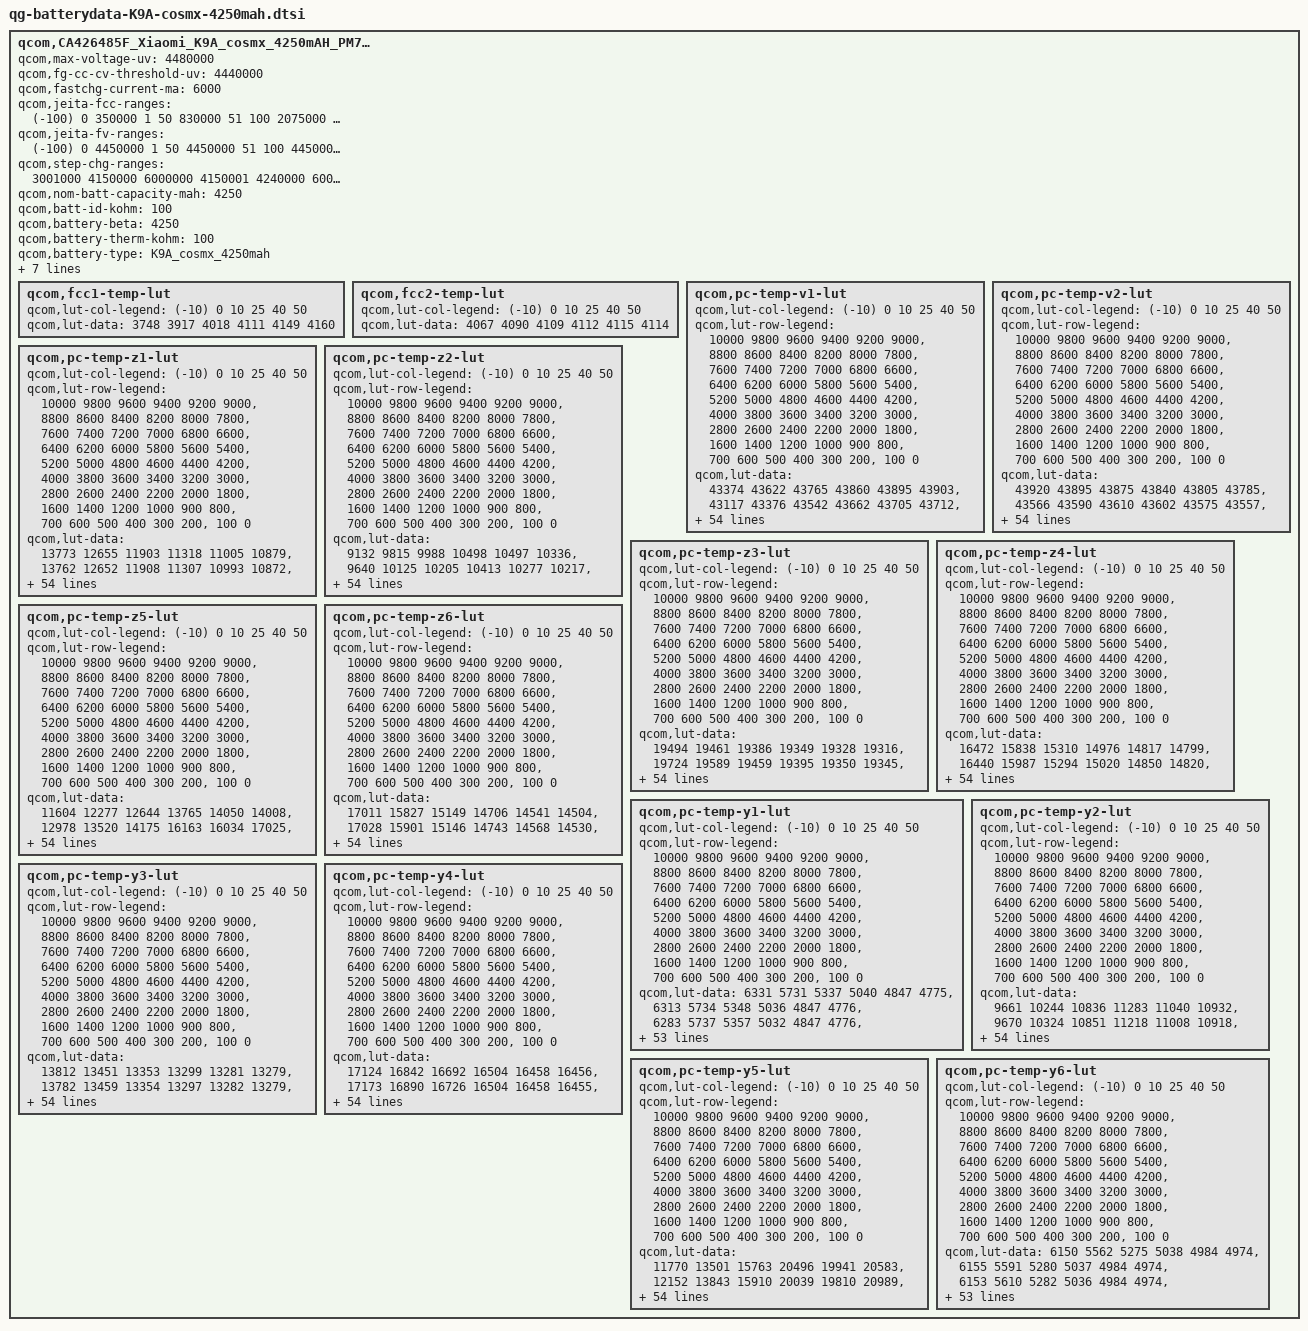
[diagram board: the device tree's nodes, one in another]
qcom,CA426485F_Xiaomi_K9A_cosmx_4250mAH_PM7150 {
	/* 4839394_Xiaomi_K9Acosmx_4250mAh_averaged_MasterSlave_Oct12th2020_DTSI */
	qcom,max-voltage-uv = <4480000>;
	qcom,fg-cc-cv-threshold-uv = <4440000>;
	qcom,fastchg-current-ma = <6000>;
	qcom,jeita-fcc-ranges = <(-100)  0   350000
				1  50  830000
				51  100  2075000
				101 150  3320000
				151 480  6000000
				481 600  2075000>;
	qcom,jeita-fv-ranges = <(-100)  0   4450000
				1   50  4450000
				51  100  4450000
				101 150  4450000
				151 480  4480000
				481 600  4100000>;
	qcom,step-chg-ranges = <3001000  4150000  6000000
				4150001  4240000  6000000
				4240001  4350000  5400000
				4350001  4400000  5400000
				4400001  4440000  5400000
				4440001  4480000  3320000>;

	qcom,nom-batt-capacity-mah = <4250>;
	qcom,batt-id-kohm = <100>;
	qcom,battery-beta = <4250>;
	qcom,battery-therm-kohm = <100>;
	qcom,battery-type = "K9A_cosmx_4250mah";
	qcom,qg-batt-profile-ver = <100>;
	qcom,taper-fcc;

	mi,six-pin-battery;
	mi,use-bq-pump;
	mi,step-chg-hysteresis = <5000>;
	mi-ffc-current-cfg = <350 850000 850000 (-500) (-600)>;	/* specification 100% current: 828mA */

	qcom,fcc1-temp-lut {
		qcom,lut-col-legend = <(-10) 0 10 25 40 50>;
		qcom,lut-data = <3748 3917 4018 4111 4149 4160>;
	};

	qcom,fcc2-temp-lut {
		qcom,lut-col-legend = <(-10) 0 10 25 40 50>;
		qcom,lut-data = <4067 4090 4109 4112 4115 4114>;
	};

	qcom,pc-temp-v1-lut {
		qcom,lut-col-legend = <(-10) 0 10 25 40 50>;
		qcom,lut-row-legend = <10000 9800 9600 9400 9200 9000>,
			<8800 8600 8400 8200 8000 7800>,
			<7600 7400 7200 7000 6800 6600>,
			<6400 6200 6000 5800 5600 5400>,
			<5200 5000 4800 4600 4400 4200>,
			<4000 3800 3600 3400 3200 3000>,
			<2800 2600 2400 2200 2000 1800>,
			<1600 1400 1200 1000 900 800>,
			<700 600 500 400 300 200>,
			<100 0>;
		qcom,lut-data = <43374 43622 43765 43860 43895 43903>,
			<43117 43376 43542 43662 43705 43712>,
			<42869 43136 43315 43452 43502 43511>,
			<42630 42899 43085 43233 43289 43302>,
			<42398 42665 42850 43007 43067 43085>,
			<42171 42428 42614 42771 42834 42857>,
			<41949 42192 42378 42533 42597 42622>,
			<41732 41963 42142 42296 42361 42386>,
			<41518 41739 41911 42061 42127 42149>,
			<41307 41521 41684 41828 41894 41914>,
			<41099 41308 41463 41598 41663 41684>,
			<40897 41100 41248 41374 41435 41459>,
			<40700 40897 41041 41157 41213 41237>,
			<40507 40699 40838 40948 40998 41021>,
			<40314 40505 40634 40745 40788 40809>,
			<40123 40319 40435 40548 40587 40606>,
			<39952 40138 40252 40358 40394 40411>,
			<39805 39966 40088 40181 40211 40224>,
			<39674 39810 39927 40017 40047 40055>,
			<39555 39668 39759 39837 39877 39885>,
			<39448 39529 39589 39603 39660 39678>,
			<39344 39382 39404 39350 39403 39427>,
			<39227 39232 39173 39155 39189 39205>,
			<39092 39080 38940 39002 39030 39041>,
			<38959 38917 38789 38872 38893 38902>,
			<38847 38759 38690 38758 38770 38776>,
			<38744 38641 38610 38660 38658 38664>,
			<38652 38550 38537 38568 38557 38561>,
			<38575 38478 38471 38481 38465 38465>,
			<38506 38418 38411 38402 38380 38376>,
			<38448 38368 38356 38332 38304 38298>,
			<38399 38324 38306 38268 38235 38227>,
			<38357 38287 38262 38213 38172 38161>,
			<38318 38253 38222 38166 38116 38098>,
			<38283 38222 38186 38124 38065 38040>,
			<38249 38195 38153 38081 38012 37977>,
			<38213 38166 38122 38041 37957 37911>,
			<38176 38124 38079 37992 37896 37838>,
			<38136 38060 38006 37920 37817 37753>,
			<38079 37979 37911 37824 37720 37655>,
			<37975 37876 37803 37719 37614 37548>,
			<37848 37743 37673 37599 37496 37426>,
			<37704 37588 37525 37460 37362 37291>,
			<37558 37431 37358 37293 37195 37129>,
			<37423 37337 37223 37159 37081 37011>,
			<37306 37237 37146 37081 37010 36952>,
			<37261 37198 37120 37060 36990 36933>,
			<37223 37166 37100 37042 36975 36915>,
			<37186 37132 37072 37023 36950 36891>,
			<37132 37055 36992 36943 36860 36792>,
			<36973 36822 36703 36635 36530 36449>,
			<36624 36362 36233 36170 36072 35991>,
			<36099 35774 35628 35576 35482 35395>,
			<35422 34983 34800 34764 34676 34578>,
			<34274 33686 33461 33486 33419 33295>,
			<30000 30000 30000 30000 30000 30000>;
	};

	qcom,pc-temp-v2-lut {
		qcom,lut-col-legend = <(-10) 0 10 25 40 50>;
		qcom,lut-row-legend = <10000 9800 9600 9400 9200 9000>,
			<8800 8600 8400 8200 8000 7800>,
			<7600 7400 7200 7000 6800 6600>,
			<6400 6200 6000 5800 5600 5400>,
			<5200 5000 4800 4600 4400 4200>,
			<4000 3800 3600 3400 3200 3000>,
			<2800 2600 2400 2200 2000 1800>,
			<1600 1400 1200 1000 900 800>,
			<700 600 500 400 300 200>,
			<100 0>;
		qcom,lut-data = <43920 43895 43875 43840 43805 43785>,
			<43566 43590 43610 43602 43575 43557>,
			<43237 43303 43351 43366 43344 43327>,
			<42935 43038 43101 43129 43113 43099>,
			<42660 42797 42858 42894 42883 42871>,
			<42398 42560 42617 42658 42651 42641>,
			<42139 42310 42376 42421 42416 42407>,
			<41886 42055 42134 42183 42179 42170>,
			<41648 41816 41896 41949 41945 41937>,
			<41415 41597 41660 41716 41713 41704>,
			<41204 41388 41428 41487 41484 41475>,
			<41054 41188 41200 41264 41261 41253>,
			<40951 41001 40976 41045 41042 41033>,
			<40818 40797 40767 40834 40830 40822>,
			<40505 40543 40582 40628 40623 40615>,
			<40072 40267 40404 40429 40424 40416>,
			<39767 40029 40207 40240 40235 40227>,
			<39577 39826 39993 40064 40061 40051>,
			<39406 39627 39770 39877 39880 39871>,
			<39212 39408 39536 39657 39677 39677>,
			<39011 39181 39296 39421 39464 39475>,
			<38815 38974 39085 39203 39253 39270>,
			<38612 38790 38897 38998 39035 39048>,
			<38429 38617 38729 38816 38840 38847>,
			<38316 38442 38585 38673 38697 38702>,
			<38241 38266 38458 38553 38580 38585>,
			<38178 38141 38336 38446 38473 38477>,
			<38116 38074 38209 38346 38372 38375>,
			<38058 38024 38093 38256 38279 38282>,
			<38001 37977 38006 38170 38196 38197>,
			<37943 37932 37936 38091 38122 38120>,
			<37884 37888 37882 38017 38051 38047>,
			<37824 37841 37844 37949 37985 37982>,
			<37761 37792 37812 37884 37921 37918>,
			<37698 37743 37776 37820 37845 37836>,
			<37631 37693 37737 37754 37753 37730>,
			<37561 37639 37692 37687 37658 37620>,
			<37488 37575 37631 37614 37568 37522>,
			<37411 37500 37551 37538 37478 37429>,
			<37333 37416 37459 37454 37387 37336>,
			<37257 37319 37345 37360 37300 37248>,
			<37181 37211 37219 37256 37207 37154>,
			<37106 37097 37097 37126 37081 37029>,
			<37033 36974 36977 36980 36941 36887>,
			<36958 36871 36869 36898 36871 36821>,
			<36881 36789 36771 36849 36832 36785>,
			<36833 36753 36727 36832 36819 36771>,
			<36772 36722 36683 36812 36802 36755>,
			<36694 36672 36628 36772 36763 36711>,
			<36561 36574 36499 36637 36610 36527>,
			<36346 36336 36216 36263 36221 36123>,
			<36053 35925 35743 35729 35705 35597>,
			<35601 35307 35095 35027 35028 34907>,
			<34891 34390 34167 34022 34100 33973>,
			<33684 32791 32537 32386 32695 32545>,
			<31203 29386 27722 28383 28528 28234>;
	};

	qcom,pc-temp-z1-lut {
		qcom,lut-col-legend = <(-10) 0 10 25 40 50>;
		qcom,lut-row-legend = <10000 9800 9600 9400 9200 9000>,
			<8800 8600 8400 8200 8000 7800>,
			<7600 7400 7200 7000 6800 6600>,
			<6400 6200 6000 5800 5600 5400>,
			<5200 5000 4800 4600 4400 4200>,
			<4000 3800 3600 3400 3200 3000>,
			<2800 2600 2400 2200 2000 1800>,
			<1600 1400 1200 1000 900 800>,
			<700 600 500 400 300 200>,
			<100 0>;
		qcom,lut-data = <13773 12655 11903 11318 11005 10879>,
			<13762 12652 11908 11307 10993 10872>,
			<13740 12643 11910 11300 10984 10867>,
			<13698 12629 11906 11293 10978 10862>,
			<13654 12621 11888 11282 10972 10856>,
			<13627 12619 11869 11268 10964 10850>,
			<13606 12617 11852 11255 10954 10843>,
			<13593 12611 11836 11246 10948 10838>,
			<13584 12578 11828 11237 10944 10835>,
			<13566 12541 11822 11234 10941 10833>,
			<13550 12520 11817 11232 10939 10831>,
			<13546 12503 11813 11231 10936 10830>,
			<13545 12489 11802 11231 10935 10829>,
			<13545 12472 11797 11231 10934 10828>,
			<13539 12455 11798 11232 10934 10828>,
			<13528 12452 11799 11234 10934 10828>,
			<13520 12446 11801 11237 10935 10829>,
			<13521 12435 11807 11237 10935 10829>,
			<13532 12430 11814 11236 10937 10830>,
			<13541 12426 11815 11235 10939 10831>,
			<13560 12425 11815 11235 10939 10832>,
			<13579 12434 11815 11237 10939 10833>,
			<13579 12449 11816 11240 10940 10834>,
			<13564 12456 11817 11247 10943 10836>,
			<13552 12454 11822 11254 10947 10840>,
			<13554 12451 11845 11258 10951 10843>,
			<13560 12451 11865 11263 10954 10846>,
			<13566 12460 11862 11266 10957 10848>,
			<13575 12469 11851 11267 10961 10851>,
			<13586 12473 11846 11269 10965 10854>,
			<13600 12480 11854 11271 10968 10856>,
			<13625 12486 11865 11273 10972 10859>,
			<13655 12487 11868 11277 10975 10862>,
			<13672 12489 11867 11281 10980 10866>,
			<13679 12494 11866 11287 10984 10871>,
			<13688 12524 11870 11293 10988 10875>,
			<13692 12561 11878 11302 10993 10879>,
			<13690 12573 11889 11309 10997 10883>,
			<13688 12569 11905 11313 11002 10886>,
			<13691 12567 11922 11317 11006 10890>,
			<13702 12576 11931 11322 11010 10894>,
			<13710 12588 11940 11330 11013 10898>,
			<13695 12590 11942 11336 11017 10901>,
			<13706 12588 11950 11341 11022 10903>,
			<13748 12614 11949 11354 11026 10906>,
			<13706 12645 11962 11352 11031 10905>,
			<13693 12612 11963 11345 11029 10906>,
			<13719 12617 11964 11349 11029 10907>,
			<13701 12620 11969 11352 11033 10909>,
			<13705 12635 11965 11360 11040 10916>,
			<13747 12654 11975 11370 11050 10923>,
			<13758 12643 12003 11389 11057 10929>,
			<13738 12680 12027 11398 11066 10940>,
			<13759 12717 12080 11419 11080 10951>,
			<13759 12717 12080 11419 11080 10951>,
			<13759 12717 12080 11419 11080 10951>;
	};

	qcom,pc-temp-z2-lut {
		qcom,lut-col-legend = <(-10) 0 10 25 40 50>;
		qcom,lut-row-legend = <10000 9800 9600 9400 9200 9000>,
			<8800 8600 8400 8200 8000 7800>,
			<7600 7400 7200 7000 6800 6600>,
			<6400 6200 6000 5800 5600 5400>,
			<5200 5000 4800 4600 4400 4200>,
			<4000 3800 3600 3400 3200 3000>,
			<2800 2600 2400 2200 2000 1800>,
			<1600 1400 1200 1000 900 800>,
			<700 600 500 400 300 200>,
			<100 0>;
		qcom,lut-data = <9132 9815 9988 10498 10497 10336>,
			<9640 10125 10205 10413 10277 10217>,
			<9871 10171 10334 10412 10238 10167>,
			<9943 10185 10339 10414 10230 10146>,
			<9983 10186 10298 10403 10220 10128>,
			<9991 10168 10256 10356 10184 10098>,
			<9988 10140 10228 10314 10139 10064>,
			<9985 10124 10204 10302 10127 10056>,
			<9984 10111 10187 10294 10134 10077>,
			<9982 10100 10173 10294 10140 10100>,
			<9979 10090 10164 10302 10135 10103>,
			<9973 10081 10167 10310 10129 10099>,
			<9965 10073 10182 10307 10128 10099>,
			<9957 10064 10200 10299 10135 10109>,
			<9950 10057 10217 10296 10145 10121>,
			<9943 10055 10233 10308 10155 10129>,
			<9936 10062 10245 10325 10169 10135>,
			<9931 10071 10251 10336 10185 10143>,
			<9926 10074 10258 10350 10204 10157>,
			<9906 10075 10272 10372 10231 10176>,
			<9752 10077 10293 10433 10295 10206>,
			<9583 10085 10315 10509 10410 10261>,
			<9581 10106 10340 10518 10460 10299>,
			<9755 10127 10362 10454 10374 10287>,
			<9921 10151 10365 10401 10261 10249>,
			<9950 10173 10352 10401 10232 10204>,
			<9959 10179 10339 10408 10227 10102>,
			<9966 10180 10337 10410 10220 10032>,
			<9973 10181 10338 10407 10182 10036>,
			<9979 10181 10341 10404 10135 10048>,
			<9985 10182 10344 10408 10128 10059>,
			<9992 10184 10348 10424 10141 10080>,
			<10000 10186 10353 10440 10159 10106>,
			<10005 10188 10360 10450 10187 10137>,
			<10008 10191 10369 10460 10232 10176>,
			<10009 10194 10377 10475 10270 10217>,
			<10009 10197 10387 10499 10302 10263>,
			<9881 10203 10397 10524 10335 10305>,
			<9685 10211 10408 10550 10379 10336>,
			<9603 10217 10418 10575 10429 10362>,
			<9586 10219 10419 10580 10449 10372>,
			<9609 10219 10415 10562 10437 10370>,
			<9600 10227 10409 10544 10421 10365>,
			<9498 10244 10395 10529 10404 10348>,
			<9173 10158 10488 10545 10414 10331>,
			<9163 10182 10448 10514 10388 10317>,
			<9166 10318 10446 10467 10403 10326>,
			<9164 10373 10446 10476 10425 10347>,
			<9158 10571 10417 10475 10462 10396>,
			<9152 10675 10419 10506 10488 10433>,
			<9139 10396 10460 10513 10368 10273>,
			<9119 9946 10315 10484 10284 10181>,
			<9097 9760 10250 10402 10255 10122>,
			<9070 9568 10129 10345 10170 10055>,
			<9070 9568 10129 10345 10170 10055>,
			<9070 9568 10129 10345 10170 10055>;
	};

	qcom,pc-temp-z3-lut {
		qcom,lut-col-legend = <(-10) 0 10 25 40 50>;
		qcom,lut-row-legend = <10000 9800 9600 9400 9200 9000>,
			<8800 8600 8400 8200 8000 7800>,
			<7600 7400 7200 7000 6800 6600>,
			<6400 6200 6000 5800 5600 5400>,
			<5200 5000 4800 4600 4400 4200>,
			<4000 3800 3600 3400 3200 3000>,
			<2800 2600 2400 2200 2000 1800>,
			<1600 1400 1200 1000 900 800>,
			<700 600 500 400 300 200>,
			<100 0>;
		qcom,lut-data = <19494 19461 19386 19349 19328 19316>,
			<19724 19589 19459 19395 19350 19345>,
			<19813 19614 19510 19411 19364 19360>,
			<19841 19622 19528 19420 19374 19367>,
			<19856 19629 19537 19424 19382 19373>,
			<19858 19638 19542 19427 19388 19377>,
			<19850 19647 19543 19429 19392 19381>,
			<19842 19651 19544 19426 19392 19382>,
			<19839 19653 19544 19422 19386 19380>,
			<19839 19654 19541 19418 19379 19377>,
			<19840 19654 19536 19416 19377 19374>,
			<19841 19651 19527 19414 19375 19371>,
			<19844 19648 19514 19410 19373 19368>,
			<19847 19645 19506 19405 19373 19366>,
			<19853 19640 19505 19401 19372 19365>,
			<19859 19635 19504 19398 19370 19363>,
			<19862 19628 19502 19396 19368 19360>,
			<19857 19621 19495 19395 19366 19358>,
			<19843 19616 19488 19395 19360 19355>,
			<19820 19611 19488 19395 19354 19352>,
			<19702 19609 19490 19403 19358 19352>,
			<19575 19611 19493 19416 19370 19359>,
			<19572 19617 19500 19417 19376 19367>,
			<19694 19623 19508 19406 19376 19376>,
			<19808 19631 19509 19397 19377 19386>,
			<19822 19638 19505 19401 19380 19389>,
			<19824 19639 19502 19413 19391 19389>,
			<19825 19636 19500 19420 19398 19389>,
			<19824 19631 19500 19423 19395 19387>,
			<19819 19627 19499 19425 19389 19382>,
			<19813 19622 19499 19424 19383 19376>,
			<19806 19618 19500 19420 19379 19369>,
			<19797 19615 19499 19416 19374 19362>,
			<19789 19612 19498 19412 19368 19355>,
			<19783 19608 19496 19407 19363 19348>,
			<19777 19602 19493 19404 19360 19346>,
			<19767 19596 19490 19401 19357 19345>,
			<19683 19590 19487 19399 19356 19346>,
			<19558 19584 19482 19397 19356 19346>,
			<19499 19578 19477 19395 19357 19346>,
			<19486 19571 19474 19393 19357 19347>,
			<19499 19564 19471 19391 19357 19350>,
			<19495 19559 19468 19387 19357 19352>,
			<19443 19550 19462 19383 19357 19351>,
			<19286 19267 19440 19374 19348 19349>,
			<19289 19262 19429 19370 19343 19340>,
			<19288 19261 19425 19366 19339 19332>,
			<19288 19261 19415 19363 19333 19329>,
			<19289 19260 19404 19355 19330 19323>,
			<19290 19260 19399 19354 19331 19322>,
			<19293 19261 19400 19356 19345 19341>,
			<19298 19263 19371 19360 19347 19340>,
			<19306 19265 19370 19360 19347 19340>,
			<19320 19269 19371 19362 19350 19345>,
			<19320 19269 19371 19362 19350 19345>,
			<19320 19269 19371 19362 19350 19345>;
	};

	qcom,pc-temp-z4-lut {
		qcom,lut-col-legend = <(-10) 0 10 25 40 50>;
		qcom,lut-row-legend = <10000 9800 9600 9400 9200 9000>,
			<8800 8600 8400 8200 8000 7800>,
			<7600 7400 7200 7000 6800 6600>,
			<6400 6200 6000 5800 5600 5400>,
			<5200 5000 4800 4600 4400 4200>,
			<4000 3800 3600 3400 3200 3000>,
			<2800 2600 2400 2200 2000 1800>,
			<1600 1400 1200 1000 900 800>,
			<700 600 500 400 300 200>,
			<100 0>;
		qcom,lut-data = <16472 15838 15310 14976 14817 14799>,
			<16440 15987 15294 15020 14850 14820>,
			<16369 15930 15258 14978 14846 14821>,
			<16200 15752 15199 14906 14814 14798>,
			<15983 15576 15093 14857 14782 14770>,
			<15817 15438 14994 14819 14758 14748>,
			<15687 15312 14930 14787 14736 14728>,
			<15573 15210 14878 14761 14722 14716>,
			<15470 15124 14837 14740 14712 14708>,
			<15372 15053 14802 14728 14705 14703>,
			<15302 14995 14776 14721 14700 14698>,
			<15267 14947 14761 14716 14697 14695>,
			<15243 14909 14750 14712 14692 14691>,
			<15230 14879 14744 14710 14687 14687>,
			<15227 14854 14741 14707 14682 14684>,
			<15226 14836 14740 14705 14679 14681>,
			<15223 14823 14737 14702 14676 14678>,
			<15200 14812 14730 14700 14674 14675>,
			<15160 14801 14724 14697 14673 14671>,
			<15147 14787 14725 14695 14672 14668>,
			<15230 14778 14731 14725 14690 14679>,
			<15325 14776 14740 14779 14745 14731>,
			<15324 14776 14788 14806 14771 14764>,
			<15224 14778 14851 14821 14769 14754>,
			<15137 14798 14865 14828 14765 14736>,
			<15139 14828 14858 14816 14754 14721>,
			<15161 14841 14847 14785 14727 14707>,
			<15180 14844 14835 14763 14708 14697>,
			<15184 14845 14820 14748 14703 14692>,
			<15185 14842 14807 14738 14700 14689>,
			<15184 14834 14796 14736 14698 14686>,
			<15178 14825 14788 14736 14695 14682>,
			<15164 14817 14782 14736 14694 14680>,
			<15149 14808 14779 14736 14694 14679>,
			<15130 14800 14775 14738 14694 14678>,
			<15110 14791 14772 14739 14695 14678>,
			<15094 14781 14767 14739 14697 14680>,
			<15132 14773 14764 14740 14699 14685>,
			<15200 14764 14762 14740 14703 14690>,
			<15231 14757 14760 14741 14708 14696>,
			<15218 14751 14755 14740 14709 14698>,
			<15182 14746 14742 14725 14698 14691>,
			<15158 14735 14731 14712 14692 14687>,
			<15160 14727 14720 14705 14694 14693>,
			<15255 14933 14685 14677 14676 14678>,
			<15250 14929 14671 14662 14659 14656>,
			<15243 14927 14665 14653 14650 14649>,
			<15230 14920 14663 14645 14639 14636>,
			<15224 14913 14666 14641 14628 14624>,
			<15207 14907 14669 14641 14628 14626>,
			<15206 14908 14679 14656 14647 14652>,
			<15227 14928 14721 14656 14649 14657>,
			<15276 14941 14728 14657 14651 14660>,
			<15349 14964 14738 14655 14648 14655>,
			<15349 14964 14738 14655 14648 14655>,
			<15349 14964 14738 14655 14648 14655>;
	};

	qcom,pc-temp-z5-lut {
		qcom,lut-col-legend = <(-10) 0 10 25 40 50>;
		qcom,lut-row-legend = <10000 9800 9600 9400 9200 9000>,
			<8800 8600 8400 8200 8000 7800>,
			<7600 7400 7200 7000 6800 6600>,
			<6400 6200 6000 5800 5600 5400>,
			<5200 5000 4800 4600 4400 4200>,
			<4000 3800 3600 3400 3200 3000>,
			<2800 2600 2400 2200 2000 1800>,
			<1600 1400 1200 1000 900 800>,
			<700 600 500 400 300 200>,
			<100 0>;
		qcom,lut-data = <11604 12277 12644 13765 14050 14008>,
			<12978 13520 14175 16163 16034 17025>,
			<13898 14064 15418 16981 17303 18657>,
			<14520 14371 16268 17512 18182 19461>,
			<15004 14750 16849 18142 19085 20213>,
			<15400 15368 17483 18803 20492 21375>,
			<15702 16153 18406 19478 21785 22696>,
			<15999 16935 19547 20243 22017 23767>,
			<16444 17691 20783 21064 22003 24779>,
			<17135 18441 22341 21759 21994 25506>,
			<17728 19219 23670 22429 22169 25615>,
			<17930 20067 24143 22845 22595 25458>,
			<18021 20891 24352 22814 23142 25507>,
			<18144 21698 24671 22669 24103 26251>,
			<18509 22529 26160 22619 25173 27322>,
			<19098 23102 28323 23019 26192 28223>,
			<19406 23448 28878 23732 27181 29135>,
			<19327 23774 27991 24522 27411 29924>,
			<19116 24120 27125 25750 26257 30737>,
			<18794 24663 28319 27395 25064 31363>,
			<17313 25557 32711 30770 25522 31165>,
			<15883 27822 36693 34592 27198 29697>,
			<16257 32356 39573 34427 27896 27862>,
			<18745 36921 41782 26947 23997 25208>,
			<21172 41795 41574 20651 19155 22400>,
			<21859 46021 37084 20778 19199 22100>,
			<22222 46730 32788 21954 22407 24204>,
			<22414 44476 31855 23489 25059 26496>,
			<22394 41615 31441 26078 26084 28002>,
			<22221 39886 31494 28977 26834 29241>,
			<22003 38394 32581 31198 27659 29485>,
			<21789 37526 34308 33213 28595 28881>,
			<21548 37263 35790 34433 29245 28251>,
			<21379 37100 37399 35031 29529 27992>,
			<21316 36816 38593 35400 29725 27713>,
			<21268 36095 39121 35431 29824 27680>,
			<21173 35407 39466 35249 29833 28758>,
			<19498 35441 39448 34944 29818 29913>,
			<16956 36117 38938 34203 29651 29600>,
			<15803 36643 38307 32992 29213 28291>,
			<15935 36240 37974 32102 29038 27687>,
			<16481 35413 37680 31556 29202 29119>,
			<16074 36150 37141 30789 29302 30177>,
			<14368 37538 36030 29357 28988 29796>,
			<10983 11872 37671 31917 27759 31535>,
			<10947 11352 33155 32114 26404 26855>,
			<10905 11312 31067 31143 26011 23585>,
			<10857 11251 26350 31745 26482 26518>,
			<10831 11206 23512 28153 30752 31455>,
			<10828 11213 22949 27688 31129 30535>,
			<10838 11276 22344 22698 26527 26530>,
			<10826 11298 15620 22377 24498 22014>,
			<10778 11218 14919 21275 22266 19796>,
			<10739 11136 14393 21096 21602 18918>,
			<10739 11136 14393 21096 21602 18918>,
			<10739 11136 14393 21096 21602 18918>;
	};

	qcom,pc-temp-z6-lut {
		qcom,lut-col-legend = <(-10) 0 10 25 40 50>;
		qcom,lut-row-legend = <10000 9800 9600 9400 9200 9000>,
			<8800 8600 8400 8200 8000 7800>,
			<7600 7400 7200 7000 6800 6600>,
			<6400 6200 6000 5800 5600 5400>,
			<5200 5000 4800 4600 4400 4200>,
			<4000 3800 3600 3400 3200 3000>,
			<2800 2600 2400 2200 2000 1800>,
			<1600 1400 1200 1000 900 800>,
			<700 600 500 400 300 200>,
			<100 0>;
		qcom,lut-data = <17011 15827 15149 14706 14541 14504>,
			<17028 15901 15146 14743 14568 14530>,
			<16987 15863 15138 14727 14569 14535>,
			<16868 15748 15116 14697 14560 14529>,
			<16713 15637 15055 14675 14550 14521>,
			<16587 15555 14994 14656 14542 14514>,
			<16479 15482 14953 14638 14534 14507>,
			<16382 15420 14918 14622 14526 14501>,
			<16298 15366 14888 14608 14517 14496>,
			<16223 15319 14863 14599 14511 14491>,
			<16173 15278 14841 14594 14507 14487>,
			<16157 15242 14826 14590 14503 14484>,
			<16147 15210 14814 14586 14500 14480>,
			<16142 15182 14806 14582 14497 14478>,
			<16143 15157 14803 14579 14495 14475>,
			<16147 15139 14801 14577 14492 14472>,
			<16149 15126 14798 14575 14490 14470>,
			<16141 15117 14792 14574 14488 14467>,
			<16125 15111 14788 14573 14484 14464>,
			<16112 15106 14789 14572 14481 14461>,
			<16098 15103 14794 14590 14491 14466>,
			<16087 15105 14803 14622 14521 14493>,
			<16089 15111 14829 14632 14536 14510>,
			<16111 15120 14861 14634 14536 14510>,
			<16140 15136 14868 14635 14536 14509>,
			<16159 15155 14865 14633 14534 14508>,
			<16176 15163 14862 14627 14530 14503>,
			<16190 15165 14858 14622 14525 14498>,
			<16196 15166 14853 14620 14521 14495>,
			<16200 15164 14850 14617 14518 14491>,
			<16202 15161 14847 14616 14514 14487>,
			<16201 15157 14845 14615 14511 14483>,
			<16197 15155 14844 14614 14508 14478>,
			<16194 15153 14844 14613 14506 14474>,
			<16193 15151 14844 14612 14503 14470>,
			<16192 15149 14844 14612 14503 14469>,
			<16191 15146 14844 14613 14503 14470>,
			<16181 15146 14844 14613 14503 14472>,
			<16166 15148 14845 14614 14505 14474>,
			<16160 15149 14847 14615 14509 14478>,
			<16166 15152 14847 14615 14510 14479>,
			<16172 15156 14847 14610 14506 14478>,
			<16177 15162 14847 14605 14504 14478>,
			<16173 15166 14846 14603 14506 14481>,
			<16156 15136 14833 14590 14494 14474>,
			<16160 15132 14825 14583 14484 14460>,
			<16158 15133 14820 14578 14479 14453>,
			<16153 15132 14816 14574 14471 14445>,
			<16163 15133 14816 14570 14466 14437>,
			<16171 15140 14820 14572 14467 14438>,
			<16187 15152 14833 14584 14485 14462>,
			<16222 15172 14844 14589 14489 14466>,
			<16276 15195 14857 14595 14492 14469>,
			<16361 15230 14881 14602 14496 14473>,
			<16361 15230 14881 14602 14496 14473>,
			<16361 15230 14881 14602 14496 14473>;
	};

	qcom,pc-temp-y1-lut {
		qcom,lut-col-legend = <(-10) 0 10 25 40 50>;
		qcom,lut-row-legend = <10000 9800 9600 9400 9200 9000>,
			<8800 8600 8400 8200 8000 7800>,
			<7600 7400 7200 7000 6800 6600>,
			<6400 6200 6000 5800 5600 5400>,
			<5200 5000 4800 4600 4400 4200>,
			<4000 3800 3600 3400 3200 3000>,
			<2800 2600 2400 2200 2000 1800>,
			<1600 1400 1200 1000 900 800>,
			<700 600 500 400 300 200>,
			<100 0>;
		qcom,lut-data = <6331 5731 5337 5040 4847 4775>,
			<6313 5734 5348 5036 4847 4776>,
			<6283 5737 5357 5032 4847 4776>,
			<6248 5738 5364 5027 4846 4776>,
			<6218 5739 5369 5023 4845 4775>,
			<6201 5738 5371 5020 4843 4774>,
			<6200 5735 5369 5018 4841 4772>,
			<6200 5731 5366 5016 4839 4770>,
			<6201 5729 5362 5015 4838 4769>,
			<6224 5729 5360 5013 4836 4768>,
			<6252 5730 5358 5012 4835 4768>,
			<6257 5731 5359 5011 4834 4767>,
			<6254 5733 5361 5009 4832 4767>,
			<6249 5734 5363 5009 4831 4766>,
			<6238 5742 5369 5009 4830 4765>,
			<6222 5753 5376 5011 4829 4764>,
			<6219 5756 5377 5012 4829 4764>,
			<6231 5756 5375 5013 4828 4765>,
			<6242 5755 5374 5013 4828 4765>,
			<6239 5754 5380 5013 4829 4765>,
			<6228 5750 5391 5013 4832 4766>,
			<6224 5751 5393 5014 4833 4766>,
			<6229 5764 5384 5018 4835 4767>,
			<6234 5777 5375 5022 4836 4769>,
			<6237 5775 5378 5025 4838 4771>,
			<6240 5764 5389 5027 4840 4772>,
			<6241 5758 5393 5028 4842 4774>,
			<6234 5755 5387 5030 4844 4776>,
			<6222 5751 5379 5033 4847 4777>,
			<6217 5750 5379 5034 4849 4780>,
			<6216 5751 5384 5036 4851 4782>,
			<6216 5754 5389 5039 4853 4784>,
			<6228 5756 5387 5043 4857 4786>,
			<6270 5759 5383 5049 4861 4788>,
			<6293 5762 5383 5054 4864 4790>,
			<6264 5766 5386 5059 4865 4792>,
			<6223 5771 5389 5062 4867 4794>,
			<6218 5767 5391 5060 4870 4796>,
			<6250 5753 5394 5057 4874 4799>,
			<6276 5744 5397 5056 4876 4800>,
			<6264 5749 5398 5062 4876 4801>,
			<6238 5758 5399 5069 4877 4802>,
			<6227 5762 5401 5075 4880 4804>,
			<6239 5764 5404 5080 4884 4808>,
			<6253 5767 5406 5087 4889 4810>,
			<6271 5769 5410 5098 4893 4812>,
			<6274 5772 5412 5100 4892 4811>,
			<6256 5778 5416 5098 4892 4810>,
			<6238 5809 5428 5095 4890 4810>,
			<6296 5805 5439 5099 4890 4812>,
			<6323 5805 5427 5100 4893 4814>,
			<6423 5820 5434 5111 4899 4821>,
			<6482 5868 5470 5126 4907 4827>,
			<6601 5959 5508 5136 4918 4834>,
			<6601 5959 5508 5136 4918 4834>,
			<6601 5959 5508 5136 4918 4834>;
	};

	qcom,pc-temp-y2-lut {
		qcom,lut-col-legend = <(-10) 0 10 25 40 50>;
		qcom,lut-row-legend = <10000 9800 9600 9400 9200 9000>,
			<8800 8600 8400 8200 8000 7800>,
			<7600 7400 7200 7000 6800 6600>,
			<6400 6200 6000 5800 5600 5400>,
			<5200 5000 4800 4600 4400 4200>,
			<4000 3800 3600 3400 3200 3000>,
			<2800 2600 2400 2200 2000 1800>,
			<1600 1400 1200 1000 900 800>,
			<700 600 500 400 300 200>,
			<100 0>;
		qcom,lut-data = <9661 10244 10836 11283 11040 10932>,
			<9670 10324 10851 11218 11008 10918>,
			<9680 10408 10864 11147 10965 10895>,
			<9689 10483 10874 11077 10920 10866>,
			<9697 10540 10881 11018 10879 10835>,
			<9701 10567 10884 10977 10853 10805>,
			<9700 10557 10883 10955 10840 10771>,
			<9698 10530 10878 10940 10829 10732>,
			<9695 10528 10873 10926 10817 10716>,
			<9688 10738 10862 10909 10802 10722>,
			<9682 10980 10854 10898 10790 10728>,
			<9681 10968 10869 10901 10785 10719>,
			<9682 10802 10937 10919 10781 10699>,
			<9683 10701 11017 10934 10780 10684>,
			<9680 10808 11113 10945 10773 10678>,
			<9676 10982 11210 10960 10764 10675>,
			<9673 11046 11264 11002 10779 10681>,
			<9672 11068 11302 11119 10861 10697>,
			<9670 11080 11320 11205 10947 10724>,
			<9670 11059 11289 11206 11007 10811>,
			<9669 10982 11224 11195 11062 10941>,
			<9668 10849 11193 11191 11081 10982>,
			<9668 10363 11185 11180 11072 10983>,
			<9667 9855 11178 11173 11061 10984>,
			<9666 9748 11167 11194 11070 10993>,
			<9666 9715 11153 11242 11091 11012>,
			<9665 9699 11130 11290 11117 11038>,
			<9665 9692 11078 11333 11156 11090>,
			<9664 9687 11014 11371 11197 11150>,
			<9664 9682 10924 11395 11222 11186>,
			<9663 9678 10655 11414 11241 11220>,
			<9663 9674 10470 11423 11261 11237>,
			<9663 9671 10596 11421 11295 11234>,
			<9663 9669 10837 11416 11328 11224>,
			<9662 9667 10895 11407 11331 11219>,
			<9662 9665 10840 11379 11316 11209>,
			<9662 9664 10745 11343 11295 11196>,
			<9662 9663 10465 11307 11264 11186>,
			<9662 9662 9980 11266 11223 11175>,
			<9661 9661 9756 11235 11203 11159>,
			<9661 9660 9714 11210 11201 11117>,
			<9661 9660 9690 11182 11200 11068>,
			<9661 9660 9680 11135 11170 11038>,
			<9660 9659 9674 11058 11104 11013>,
			<9660 9659 9669 10990 11014 10922>,
			<9658 9659 9665 10941 10937 10813>,
			<9658 9658 9664 10938 10952 10820>,
			<9656 9658 9663 10944 10979 10822>,
			<9656 9657 9666 11012 11010 10826>,
			<9655 9657 9664 11030 10964 10849>,
			<9653 9656 9661 10932 10959 10799>,
			<9650 9654 9658 10794 10893 10723>,
			<9649 9651 9656 10656 10772 10635>,
			<9648 9649 9653 10575 10693 10467>,
			<9648 9649 9653 10575 10693 10467>,
			<9648 9649 9653 10575 10693 10467>;
	};

	qcom,pc-temp-y3-lut {
		qcom,lut-col-legend = <(-10) 0 10 25 40 50>;
		qcom,lut-row-legend = <10000 9800 9600 9400 9200 9000>,
			<8800 8600 8400 8200 8000 7800>,
			<7600 7400 7200 7000 6800 6600>,
			<6400 6200 6000 5800 5600 5400>,
			<5200 5000 4800 4600 4400 4200>,
			<4000 3800 3600 3400 3200 3000>,
			<2800 2600 2400 2200 2000 1800>,
			<1600 1400 1200 1000 900 800>,
			<700 600 500 400 300 200>,
			<100 0>;
		qcom,lut-data = <13812 13451 13353 13299 13281 13279>,
			<13782 13459 13354 13297 13282 13279>,
			<13754 13464 13355 13295 13282 13280>,
			<13727 13467 13356 13294 13282 13280>,
			<13703 13468 13357 13294 13283 13281>,
			<13680 13468 13358 13294 13283 13282>,
			<13661 13466 13360 13294 13284 13282>,
			<13644 13461 13362 13296 13284 13283>,
			<13625 13460 13363 13296 13285 13283>,
			<13597 13475 13363 13297 13286 13284>,
			<13573 13493 13363 13297 13286 13284>,
			<13573 13483 13360 13298 13287 13284>,
			<13590 13436 13353 13300 13287 13285>,
			<13601 13407 13349 13301 13288 13286>,
			<13582 13406 13352 13301 13288 13286>,
			<13549 13406 13357 13302 13288 13286>,
			<13539 13403 13357 13302 13289 13287>,
			<13542 13393 13351 13302 13292 13288>,
			<13546 13381 13343 13301 13294 13289>,
			<13552 13369 13337 13299 13293 13288>,
			<13561 13356 13330 13296 13290 13288>,
			<13565 13352 13324 13294 13287 13286>,
			<13559 13359 13320 13290 13283 13282>,
			<13550 13368 13316 13288 13280 13279>,
			<13552 13363 13313 13288 13280 13278>,
			<13575 13342 13310 13288 13280 13278>,
			<13605 13330 13309 13288 13280 13278>,
			<13632 13340 13308 13288 13279 13278>,
			<13662 13360 13307 13288 13278 13277>,
			<13694 13380 13306 13287 13278 13277>,
			<13729 13402 13303 13286 13278 13276>,
			<13765 13428 13301 13286 13278 13276>,
			<13800 13458 13304 13286 13278 13277>,
			<13834 13493 13309 13286 13279 13278>,
			<13869 13536 13313 13286 13279 13278>,
			<13905 13591 13316 13286 13278 13277>,
			<13940 13651 13320 13286 13278 13276>,
			<13972 13709 13328 13286 13278 13276>,
			<14002 13768 13343 13286 13278 13276>,
			<14031 13822 13359 13286 13278 13277>,
			<14060 13871 13376 13288 13279 13278>,
			<14091 13915 13396 13290 13281 13279>,
			<14128 13950 13425 13291 13280 13278>,
			<14172 13977 13469 13292 13279 13277>,
			<14236 14013 13535 13295 13280 13278>,
			<14349 14066 13627 13301 13285 13283>,
			<14431 14114 13684 13306 13288 13286>,
			<14566 14179 13718 13310 13290 13287>,
			<14691 14182 13636 13306 13289 13286>,
			<14758 14236 13675 13304 13286 13283>,
			<15278 14443 13773 13301 13283 13281>,
			<16888 14867 13974 13304 13287 13283>,
			<21144 16413 14316 13313 13290 13287>,
			<36375 22612 15178 13333 13296 13295>,
			<36375 22612 15178 13333 13296 13295>,
			<36375 22612 15178 13333 13296 13295>;
	};

	qcom,pc-temp-y4-lut {
		qcom,lut-col-legend = <(-10) 0 10 25 40 50>;
		qcom,lut-row-legend = <10000 9800 9600 9400 9200 9000>,
			<8800 8600 8400 8200 8000 7800>,
			<7600 7400 7200 7000 6800 6600>,
			<6400 6200 6000 5800 5600 5400>,
			<5200 5000 4800 4600 4400 4200>,
			<4000 3800 3600 3400 3200 3000>,
			<2800 2600 2400 2200 2000 1800>,
			<1600 1400 1200 1000 900 800>,
			<700 600 500 400 300 200>,
			<100 0>;
		qcom,lut-data = <17124 16842 16692 16504 16458 16456>,
			<17173 16890 16726 16504 16458 16455>,
			<17228 16953 16760 16504 16458 16455>,
			<17278 17016 16789 16504 16458 16454>,
			<17317 17067 16810 16504 16457 16454>,
			<17336 17092 16820 16503 16457 16453>,
			<17330 17090 16815 16503 16457 16453>,
			<17314 17080 16804 16501 16457 16453>,
			<17308 17065 16797 16501 16457 16453>,
			<17337 17029 16793 16503 16458 16453>,
			<17379 16995 16791 16506 16459 16454>,
			<17403 17023 16797 16509 16462 16455>,
			<17420 17147 16820 16513 16465 16457>,
			<17428 17222 16843 16518 16469 16460>,
			<17323 17160 16862 16527 16475 16463>,
			<17117 17052 16878 16540 16481 16468>,
			<17011 16997 16877 16560 16491 16476>,
			<16976 16976 16857 16593 16507 16488>,
			<16943 16953 16828 16613 16521 16501>,
			<16885 16912 16785 16604 16529 16512>,
			<16806 16856 16728 16580 16534 16523>,
			<16742 16802 16685 16554 16531 16523>,
			<16692 16749 16652 16518 16496 16489>,
			<16655 16699 16627 16492 16463 16458>,
			<16648 16652 16611 16488 16460 16455>,
			<16647 16606 16601 16486 16460 16455>,
			<16647 16586 16585 16486 16460 16455>,
			<16648 16587 16549 16489 16463 16457>,
			<16651 16589 16513 16493 16469 16461>,
			<16655 16593 16505 16497 16474 16466>,
			<16659 16602 16512 16501 16482 16473>,
			<16664 16614 16520 16503 16489 16481>,
			<16668 16626 16530 16503 16497 16492>,
			<16673 16640 16545 16502 16504 16503>,
			<16677 16651 16562 16500 16504 16503>,
			<16681 16658 16588 16490 16491 16489>,
			<16685 16663 16614 16483 16476 16475>,
			<16686 16669 16634 16482 16467 16469>,
			<16687 16675 16651 16482 16459 16464>,
			<16688 16679 16658 16483 16458 16463>,
			<16692 16680 16659 16493 16465 16472>,
			<16703 16681 16660 16505 16473 16480>,
			<16718 16682 16664 16511 16467 16471>,
			<16748 16687 16678 16514 16453 16448>,
			<16787 16697 16707 16524 16456 16452>,
			<16841 16722 16778 16551 16480 16488>,
			<16858 16746 16857 16581 16518 16532>,
			<16866 16777 16915 16601 16549 16564>,
			<16864 16770 16871 16596 16555 16566>,
			<16782 16765 16895 16594 16534 16519>,
			<16812 16759 16897 16545 16473 16469>,
			<17067 16756 16892 16552 16473 16467>,
			<17781 16992 16900 16577 16480 16470>,
			<21185 19213 17106 16620 16514 16504>,
			<21185 19213 17106 16620 16514 16504>,
			<21185 19213 17106 16620 16514 16504>;
	};

	qcom,pc-temp-y5-lut {
		qcom,lut-col-legend = <(-10) 0 10 25 40 50>;
		qcom,lut-row-legend = <10000 9800 9600 9400 9200 9000>,
			<8800 8600 8400 8200 8000 7800>,
			<7600 7400 7200 7000 6800 6600>,
			<6400 6200 6000 5800 5600 5400>,
			<5200 5000 4800 4600 4400 4200>,
			<4000 3800 3600 3400 3200 3000>,
			<2800 2600 2400 2200 2000 1800>,
			<1600 1400 1200 1000 900 800>,
			<700 600 500 400 300 200>,
			<100 0>;
		qcom,lut-data = <11770 13501 15763 20496 19941 20583>,
			<12152 13843 15910 20039 19810 20989>,
			<12731 14506 16068 19217 19658 21241>,
			<13366 15280 16238 18274 19487 21375>,
			<13919 15958 16418 17457 19298 21429>,
			<14250 16326 16607 17012 19094 21439>,
			<14341 16364 16845 16953 18875 21354>,
			<14394 16376 17098 16928 18638 21094>,
			<14405 16470 17173 16859 18381 20781>,
			<14272 18104 17021 16457 18092 20289>,
			<14113 19955 16732 15985 17775 19719>,
			<14949 19685 16143 15795 17418 19238>,
			<18838 17823 15012 15713 16988 18753>,
			<21500 16720 14454 15615 16522 18212>,
			<19946 17274 15801 15243 15873 17480>,
			<17073 18299 18027 14820 15298 16729>,
			<16311 19051 19314 14763 15220 16213>,
			<17723 19718 20155 14881 15360 15758>,
			<19627 20338 20756 15098 15608 15524>,
			<21210 20808 21153 16523 16943 16708>,
			<22817 21229 21453 19021 19136 19020>,
			<23384 21884 21688 20062 19812 19958>,
			<19488 23565 21848 20295 19802 20219>,
			<14267 25123 22030 20465 19782 20352>,
			<13275 23540 22406 20699 19789 20343>,
			<13287 17081 23057 21013 19793 20277>,
			<13310 13278 23776 21336 19724 20134>,
			<13409 13420 24735 21771 18723 19094>,
			<13609 13720 25538 22151 17563 17799>,
			<13780 14001 24742 22252 17457 17268>,
			<13915 14307 20513 22263 17688 16879>,
			<14039 14575 17465 22335 18006 16697>,
			<14156 14727 17839 23295 18708 17395>,
			<14271 14839 19011 24688 19881 18816>,
			<14355 15065 19409 25001 21224 20067>,
			<14411 15884 19420 24827 23099 21428>,
			<14436 16756 19428 24516 24292 22300>,
			<14395 17002 19211 23523 23815 22455>,
			<14270 17044 18583 21754 22645 22538>,
			<14142 17063 17994 20668 22138 22551>,
			<14044 16879 17523 20189 22225 22425>,
			<13952 16451 17042 19775 22323 22192>,
			<13907 15939 16450 19192 22055 21905>,
			<13905 15100 15770 18510 21264 21432>,
			<13940 14715 15191 17837 19925 19566>,
			<14257 14551 14525 17080 17791 16237>,
			<14517 14550 14277 16570 16404 15061>,
			<14929 14642 14205 16405 15712 14553>,
			<15653 15116 15637 17505 16356 15037>,
			<16749 16246 15918 17647 16337 15251>,
			<15708 16428 15664 18358 17913 16769>,
			<13239 15860 14477 17916 19945 16921>,
			<10824 12290 13412 17707 20501 17727>,
			<9457 9810 11930 18852 24223 25614>,
			<9457 9810 11930 18852 24223 25614>,
			<9457 9810 11930 18852 24223 25614>;
	};

	qcom,pc-temp-y6-lut {
		qcom,lut-col-legend = <(-10) 0 10 25 40 50>;
		qcom,lut-row-legend = <10000 9800 9600 9400 9200 9000>,
			<8800 8600 8400 8200 8000 7800>,
			<7600 7400 7200 7000 6800 6600>,
			<6400 6200 6000 5800 5600 5400>,
			<5200 5000 4800 4600 4400 4200>,
			<4000 3800 3600 3400 3200 3000>,
			<2800 2600 2400 2200 2000 1800>,
			<1600 1400 1200 1000 900 800>,
			<700 600 500 400 300 200>,
			<100 0>;
		qcom,lut-data = <6150 5562 5275 5038 4984 4974>,
			<6155 5591 5280 5037 4984 4974>,
			<6153 5610 5282 5036 4984 4974>,
			<6146 5621 5284 5034 4984 4975>,
			<6136 5626 5285 5033 4984 4975>,
			<6124 5628 5285 5032 4985 4975>,
			<6107 5623 5282 5032 4985 4976>,
			<6085 5611 5276 5032 4985 4976>,
			<6068 5606 5271 5032 4985 4976>,
			<6055 5605 5267 5032 4986 4976>,
			<6047 5606 5264 5033 4987 4977>,
			<6050 5607 5264 5034 4988 4978>,
			<6068 5611 5264 5035 4989 4979>,
			<6080 5613 5265 5038 4990 4980>,
			<6040 5599 5271 5041 4992 4981>,
			<5964 5574 5280 5045 4994 4983>,
			<5934 5558 5280 5050 4998 4985>,
			<5929 5550 5270 5059 5005 4989>,
			<5925 5542 5257 5065 5009 4993>,
			<5917 5529 5241 5061 5009 4996>,
			<5905 5513 5221 5052 5009 4998>,
			<5894 5500 5207 5042 5007 4997>,
			<5882 5491 5196 5030 4994 4985>,
			<5872 5484 5189 5021 4982 4973>,
			<5874 5476 5186 5021 4981 4972>,
			<5894 5468 5184 5021 4981 4972>,
			<5920 5464 5182 5021 4981 4972>,
			<5943 5480 5176 5022 4982 4973>,
			<5968 5512 5170 5025 4983 4974>,
			<5995 5543 5170 5026 4985 4975>,
			<6022 5577 5175 5028 4987 4977>,
			<6050 5613 5184 5029 4990 4979>,
			<6079 5652 5198 5030 4993 4983>,
			<6110 5695 5219 5031 4995 4987>,
			<6139 5742 5242 5031 4995 4987>,
			<6168 5794 5270 5029 4992 4983>,
			<6196 5848 5300 5028 4988 4978>,
			<6222 5899 5332 5029 4985 4977>,
			<6245 5949 5365 5030 4983 4976>,
			<6269 5995 5401 5032 4983 4976>,
			<6295 6036 5439 5038 4987 4979>,
			<6322 6074 5482 5046 4990 4983>,
			<6358 6107 5533 5052 4989 4980>,
			<6408 6134 5595 5059 4984 4973>,
			<6478 6170 5678 5070 4987 4975>,
			<6593 6227 5788 5089 4999 4990>,
			<6672 6275 5867 5104 5012 5004>,
			<6799 6340 5916 5113 5021 5014>,
			<6904 6343 5825 5101 5022 5014>,
			<6947 6386 5868 5098 5014 4998>,
			<7392 6555 5964 5085 4995 4983>,
			<8761 6905 6144 5099 4998 4985>,
			<12079 8191 6436 5130 5004 4989>,
			<23337 13073 7190 5181 5021 5007>,
			<23337 13073 7190 5181 5021 5007>,
			<23337 13073 7190 5181 5021 5007>;
	};

};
